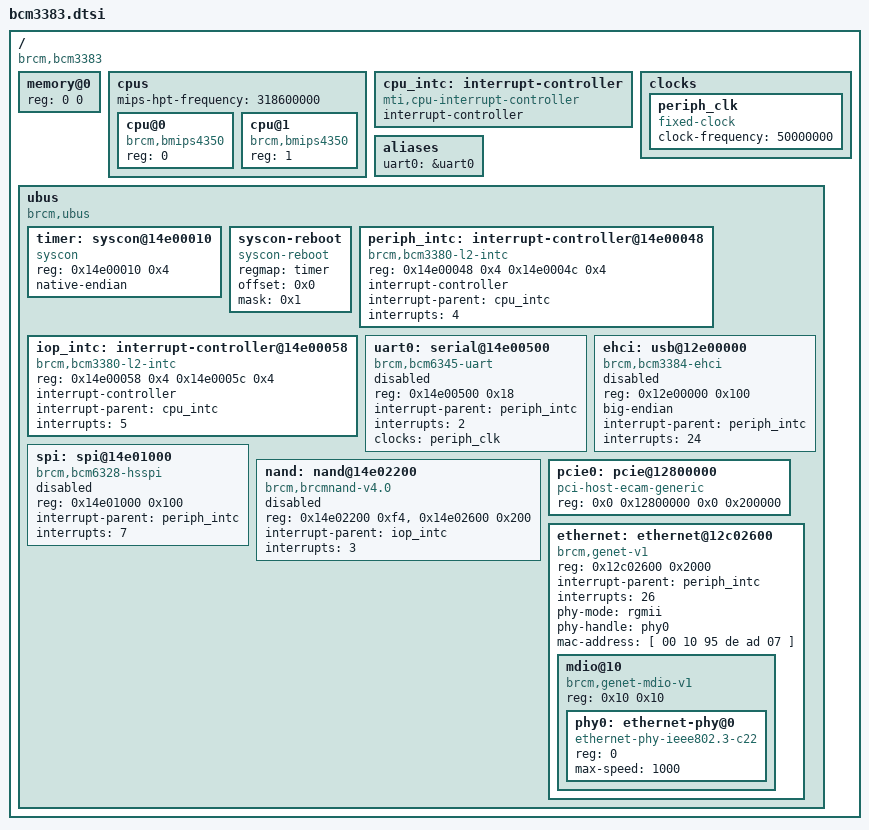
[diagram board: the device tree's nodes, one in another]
/ {
	#address-cells = <1>;
	#size-cells = <1>;
	compatible = "brcm,bcm3383";

	memory@0 {
		device_type = "memory";

		/* Typical ranges.  The bootloader should fill these in. */
		reg = <0 0>;
	};

	cpus {
		#address-cells = <1>;
		#size-cells = <0>;

		/* 1/2 of the CPU core clock (standard MIPS behavior) */
		//mips-hpt-frequency = <300000000>;
		//mips-hpt-frequency = <637200000>;
		mips-hpt-frequency = <318600000>;

		cpu@0 {
			compatible = "brcm,bmips4350";
			device_type = "cpu";
			reg = <0>;
		};

		cpu@1 {
			compatible = "brcm,bmips4350";
			device_type = "cpu";
			reg = <1>;
		};
	};

	cpu_intc: interrupt-controller {
		#address-cells = <0>;
		compatible = "mti,cpu-interrupt-controller";

		interrupt-controller;
		#interrupt-cells = <1>;
	};

	clocks {
		periph_clk: periph_clk {
			compatible = "fixed-clock";
			#clock-cells = <0>;
			clock-frequency = <50000000>;
		};
	};

	aliases {
		uart0 = &uart0;
	};

	ubus {
		#address-cells = <1>;
		#size-cells = <1>;

		compatible = "brcm,ubus", "simple-bus";
		ranges;
		/* No dma-ranges on Viper. */

		timer: syscon@14e00010 {
			compatible = "syscon";
			reg = <0x14e00010 0x4>;
			native-endian;
		};

		syscon-reboot {
			compatible = "syscon-reboot";
			regmap = <&timer>;
			offset = <0x0>;
			mask = <0x1>;
		};

		periph_intc: interrupt-controller@14e00048 {
			compatible = "brcm,bcm3380-l2-intc";
			reg = <0x14e00048 0x4 0x14e0004c 0x4>;
			interrupt-controller;
			#interrupt-cells = <1>;
			interrupt-parent = <&cpu_intc>;
			interrupts = <4>;
		};

		iop_intc: interrupt-controller@14e00058 {
			compatible = "brcm,bcm3380-l2-intc";
			reg = <0x14e00058 0x4 0x14e0005c 0x4>;
			interrupt-controller;
			#interrupt-cells = <1>;
			interrupt-parent = <&cpu_intc>;
			interrupts = <5>;
		};

		uart0: serial@14e00500 {
			compatible = "brcm,bcm6345-uart";
			reg = <0x14e00500 0x18>;
			interrupt-parent = <&periph_intc>;
			interrupts = <2>;
			clocks = <&periph_clk>;
			status = "disabled";
		};

		ehci: usb@12e00000 {
			compatible = "brcm,bcm3384-ehci", "generic-ehci";
			reg = <0x12e00000 0x100>;
			big-endian;
			interrupt-parent = <&periph_intc>;
			interrupts = <24>;
			status = "disabled";
		};

		spi: spi@14e01000 {
			compatible = "brcm,bcm6328-hsspi";
			reg = <0x14e01000 0x100>;

			#address-cells = <1>;
			#size-cells = <1>;

			interrupt-parent = <&periph_intc>;
			interrupts = <7>;

			status = "disabled";
		};

		nand: nand@14e02200 {
			compatible = "brcm,brcmnand-v4.0", "brcm,brcmnand";
			reg-names = "nand", "nand-cache";
			reg = <0x14e02200 0xf4>, <0x14e02600 0x200>;

			#address-cells = <1>;
			#size-cells = <0>;

			interrupt-parent = <&iop_intc>;
			interrupts = <3>;

			status = "disabled";
		};

		pcie0: pcie@12800000 {
			compatible = "pci-host-ecam-generic";
			device_type = "pci";
			reg = <0x0 0x12800000 0x0 0x200000>;
			ranges = <0x01000000 0x0 0x01000000  0x0 0x01000000  0x0 0x00010000>;

			#address-cells = <3>;
			#size-cells = <2>;

			status = "okay";
		};

		ethernet: ethernet@12c02600 {
			compatible = "brcm,genet-v1";
			reg = <0x12c02600 0x2000>;

			#address-cells = <1>;
			#size-cells = <1>;

			interrupt-parent = <&periph_intc>;
			interrupts = <26>;

			phy-mode = "rgmii";
			phy-handle = <&phy0>;
			mac-address = [ 00 10 95 de ad 07 ];

			status = "okay";

			mdio@10 {
				compatible = "brcm,genet-mdio-v1";
				reg = <0x10 0x10>;

				#address-cells = <1>;
				#size-cells = <0>;

				phy0: ethernet-phy@0 {
					compatible = "ethernet-phy-ieee802.3-c22";
					reg = <0>;
					max-speed = <1000>;
				};
			};


		};
	};
};
